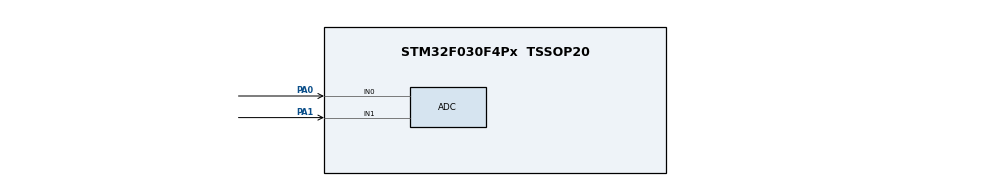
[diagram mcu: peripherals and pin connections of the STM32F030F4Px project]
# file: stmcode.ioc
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ADC.ContinuousConvMode=DISABLE
ADC.DiscontinuousConvMode=ENABLE
ADC.EOCSelection=ADC_EOC_SINGLE_CONV
ADC.Overrun=ADC_OVR_DATA_OVERWRITTEN
ADC.SamplingTime=ADC_SAMPLETIME_55CYCLES_5
Mcu.Family=STM32F0
Mcu.Name=STM32F030F4Px
Mcu.Package=TSSOP20
NVIC.ADC1_IRQn=true\:0\:0\:false\:false\:true\:true\:true\:true
PA0.Mode=IN0
PA0.Signal=ADC_IN0
PA1.Mode=IN1
PA1.Signal=ADC_IN1
ProjectManager.HeapSize=0x200
ProjectManager.StackSize=0x400
ProjectManager.TargetToolchain=Makefile
board=custom

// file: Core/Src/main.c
/* USER CODE BEGIN Header */
/**
  ******************************************************************************
  * @file           : main.c
  * @brief          : Main program body
  ******************************************************************************
  * @attention
  *
  * Copyright (c) 2026 STMicroelectronics.
  * All rights reserved.
  *
  * This software is licensed under terms that can be found in the LICENSE file
  * in the root directory of this software component.
  * If no LICENSE file comes with this software, it is provided AS-IS.
  *
  ******************************************************************************
  */
/* USER CODE END Header */
#include "main.h"
#include "adc.h"
#include "gpio.h"

void SystemClock_Config(void);

/* USER CODE BEGIN 0 */

extern void applicationMain(void);

/* USER CODE END 0 */

int main(void)
{

  /* MCU Configuration--------------------------------------------------------*/

  /* Reset of all peripherals, Initializes the Flash interface and the Systick. */
  HAL_Init();

  /* Configure the system clock */
  SystemClock_Config();

  /* Initialize all configured peripherals */
  MX_GPIO_Init();
  MX_ADC_Init();

  /* Infinite loop */
  /* USER CODE BEGIN WHILE */
  while (1)
  {
    applicationMain();
    /* USER CODE END WHILE */

  }
}

void SystemClock_Config(void)
{
  RCC_OscInitTypeDef RCC_OscInitStruct = {0};
  RCC_ClkInitTypeDef RCC_ClkInitStruct = {0};

  /** Initializes the RCC Oscillators according to the specified parameters
  * in the RCC_OscInitTypeDef structure.
  */
  RCC_OscInitStruct.OscillatorType = RCC_OSCILLATORTYPE_HSI|RCC_OSCILLATORTYPE_HSI14;
  RCC_OscInitStruct.HSIState = RCC_HSI_ON;
  RCC_OscInitStruct.HSI14State = RCC_HSI14_ON;
  RCC_OscInitStruct.HSICalibrationValue = RCC_HSICALIBRATION_DEFAULT;
  RCC_OscInitStruct.HSI14CalibrationValue = 16;
  RCC_OscInitStruct.PLL.PLLState = RCC_PLL_NONE;
  if (HAL_RCC_OscConfig(&RCC_OscInitStruct) != HAL_OK)
  {
    Error_Handler();
  }

  /** Initializes the CPU, AHB and APB buses clocks
  */
  RCC_ClkInitStruct.ClockType = RCC_CLOCKTYPE_HCLK|RCC_CLOCKTYPE_SYSCLK
                              |RCC_CLOCKTYPE_PCLK1;
  RCC_ClkInitStruct.SYSCLKSource = RCC_SYSCLKSOURCE_HSI;
  RCC_ClkInitStruct.AHBCLKDivider = RCC_SYSCLK_DIV1;
  RCC_ClkInitStruct.APB1CLKDivider = RCC_HCLK_DIV1;

  if (HAL_RCC_ClockConfig(&RCC_ClkInitStruct, FLASH_LATENCY_0) != HAL_OK)
  {
    Error_Handler();
  }
}

void Error_Handler(void)
{
  __disable_irq();
  while (1)
  {
  }
}
